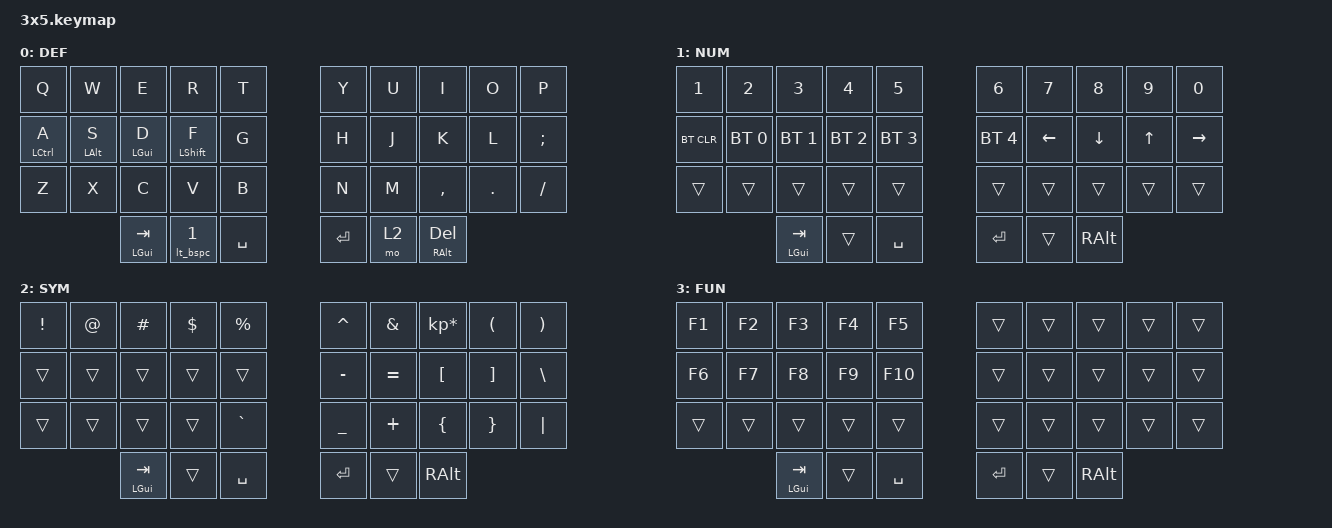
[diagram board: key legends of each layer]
/*
 * Copyright (c) 2020 The ZMK Contributors
 *
 * SPDX-License-Identifier: MIT
 */

#include <behaviors.dtsi>
#include <dt-bindings/zmk/keys.h>
#include <dt-bindings/zmk/bt.h>

// Layer aliases
#define DEF 0
#define NUM 1
#define SUM 2
#define NAV 3

#include "combos.dtsi"

// Behavior configuration
&mt {
    flavor = "hold-preferred";
    tapping-term-ms = <150>;
};

&lt {
    flavor = "balanced";
    tapping-term-ms = <150>;
};

&caps_word {
    continue-list = <UNDERSCORE MINUS BSPC DEL N1 N2 N3 N4 N5 N6 N7 N8 N9 N0>;
};

/ {
    behaviors {
        am: alpha_mods {
            compatible = "zmk,behavior-hold-tap";
            label = "ALPHA_MT";
            #binding-cells = <2>;
            tapping-term-ms = <250>;
            quick-tap-ms = <150>;
            flavor = "tap-preferred";
            bindings = <&kp>, <&kp>;
        };
        as: alpha_shift {
            compatible = "zmk,behavior-hold-tap";
            label = "ALPHA_SFT";
            #binding-cells = <2>;
            tapping-term-ms = <200>;
            quick-tap-ms = <150>;
            flavor = "tap-preferred";
            bindings = <&kp>, <&kp>;
        };

        // Easy alt-tab with alt+backspace thumb using mod-morphs
        bstab: backspace_tab {
            compatible = "zmk,behavior-mod-morph";
            label = "BSPC_TAB";
            #binding-cells = <0>;
            bindings = <&kp BSPC>, <&kp TAB>;
            mods = <MOD_LALT>;
        };
        lt_bspc: layer_tap_backspace_tab {
            compatible = "zmk,behavior-hold-tap";
            label = "LT_BT";
            #binding-cells = <2>;
            tapping-term-ms = <150>;
            flavor = "balanced";
            bindings = <&mo>, <&bstab>;
        };
    };

    cond_layers {
        compatible = "zmk,conditional-layers";
        // Define FUN layer as tri-state
        func_tristate {
            if-layers = <NAV SYM>;
            then-layer = <FUN>;
        };
    };

    macros {
        ZMK_MACRO(inv_qm,
            wait-ms = <10>;
            tap-ms = <10>;
            bindings
                = <&macro_press &kp LALT>
                , <&macro_tap &kp KP_N1 &kp KP_N6 &kp KP_N8>
                , <&macro_release &kp LALT>;
        )
    };

    keymap {
        compatible = "zmk,keymap";

        default_layer {
            label = "DEF";
            bindings = <
    /* ╭─────────────┬─────────────┬─────────────┬─────────────┬─────────────╮╭─────────────┬─────────────┬─────────────┬─────────────┬─────────────╮*/
         &kp Q         &kp W         &kp E         &kp R         &kp T          &kp Y         &kp U         &kp I         &kp O         &kp P
    /*
    ├─────────────┼─────────────┼─────────────┼─────────────┼─────────────┤├─────────────┼─────────────┼─────────────┼─────────────┼─────────────┤*/
      &am LCTRL A   &am LALT S     &am LGUI D   &as LSHFT F      &kp G          &kp H         &kp J         &kp K         &kp L        &kp SEMI
    /*
    ├─────────────┼─────────────┼─────────────┼─────────────┼─────────────┤├─────────────┼─────────────┼─────────────┼─────────────┼─────────────┤
    */
         &kp Z         &kp X         &kp C         &kp V         &kp B          &kp N         &kp M       &kp COMMA      &kp DOT      &kp FSLH
    /*
    ├─────────────┼─────────────┼─────────────┼─────────────┼─────────────┤├─────────────┼─────────────┼─────────────┼─────────────┼─────────────┤*/
                                  &mt LGUI TAB   &lt_bspc 1    &kp SPACE       &kp RET       &mo 2       &mt RALT DEL
    /*
                                ╰─────────────┴─────────────┴─────────────╯╰─────────────┴─────────────┴─────────────╯
    */
            >;
        };

        numbers {
            label = "NUM";
            bindings = <
    /* ╭─────────────┬─────────────┬─────────────┬─────────────┬─────────────╮╭─────────────┬─────────────┬─────────────┬─────────────┬─────────────╮*/
         &kp N1         &kp N2         &kp N3         &kp N4     &kp N5         &kp N6       &kp N7        &kp N8        &kp N9        &kp N0
    /*
    ├─────────────┼─────────────┼─────────────┼─────────────┼─────────────┤├─────────────┼─────────────┼─────────────┼─────────────┼─────────────┤*/
      &bt BT_CLR    &bt BT_SEL 0 &bt BT_SEL 1  &bt BT_SEL 2  &bt BT_SEL 3   &bt BT_SEL 4    &kp LEFT       &kp DOWN      &kp UP       &kp RIGHT
    /*
    ├─────────────┼─────────────┼─────────────┼─────────────┼─────────────┤├─────────────┼─────────────┼─────────────┼─────────────┼─────────────┤
    */
         &trans       &trans         &trans        &trans        &trans        &trans        &trans        &trans        &trans        &trans
    /*
    ├─────────────┼─────────────┼─────────────┼─────────────┼─────────────┤├─────────────┼─────────────┼─────────────┼─────────────┼─────────────┤*/
                                  &mt LGUI TAB    &trans       &kp SPACE        &kp RET      &trans        &kp RALT
    /*
                                ╰─────────────┴─────────────┴─────────────╯╰─────────────┴─────────────┴─────────────╯
    */
            >;
        };

        symbols {
            label = "SYM";
            bindings = <
    /* ╭─────────────┬─────────────┬─────────────┬─────────────┬─────────────╮╭─────────────┬─────────────┬─────────────┬─────────────┬─────────────╮*/
        &kp EXCL      &kp AT       &kp HASH       &kp DLLR     &kp PRCNT      &kp CARET     &kp AMPS   &kp KP_MULTIPLY   &kp LPAR     &kp RPAR
    /*
    ├─────────────┼─────────────┼─────────────┼─────────────┼─────────────┤├─────────────┼─────────────┼─────────────┼─────────────┼─────────────┤*/
        &trans        &trans        &trans        &trans         &trans       &kp MINUS     &kp EQUAL     &kp LBKT      &kp RBKT      &kp BSLH
    /*
    ├─────────────┼─────────────┼─────────────┼─────────────┼─────────────┤├─────────────┼─────────────┼─────────────┼─────────────┼─────────────┤
    */
         &trans       &trans         &trans        &trans      &kp GRAVE      &kp UNDER     &kp PLUS      &kp LBRC      &kp RBRC      &kp PIPE
    /*
    ├─────────────┼─────────────┼─────────────┼─────────────┼─────────────┤├─────────────┼─────────────┼─────────────┼─────────────┼─────────────┤*/
                                  &mt LGUI TAB    &trans       &kp SPACE        &kp RET      &trans        &kp RALT
    /*
                                ╰─────────────┴─────────────┴─────────────╯╰─────────────┴─────────────┴─────────────╯
    */
            >;
        };

        function {
            label = "FUN";
            bindings = <
    /* ╭─────────────┬─────────────┬─────────────┬─────────────┬─────────────╮╭─────────────┬─────────────┬─────────────┬─────────────┬─────────────╮*/
        &kp F1        &kp F2        &kp F3        &kp F4        &kp F5         &trans        &trans        &trans        &trans        &trans
    /*
    ├─────────────┼─────────────┼─────────────┼─────────────┼─────────────┤├─────────────┼─────────────┼─────────────┼─────────────┼─────────────┤*/
        &kp F6        &kp F7        &kp F8        &kp F9        &kp F10        &trans        &trans        &trans        &trans        &trans
    /*
    ├─────────────┼─────────────┼─────────────┼─────────────┼─────────────┤├─────────────┼─────────────┼─────────────┼─────────────┼─────────────┤
    */
         &trans       &trans         &trans        &trans      &trans          &trans        &trans        &trans        &trans        &trans
    /*
    ├─────────────┼─────────────┼─────────────┼─────────────┼─────────────┤├─────────────┼─────────────┼─────────────┼─────────────┼─────────────┤*/
                                  &mt LGUI TAB    &trans       &kp SPACE        &kp RET      &trans        &kp RALT
    /*
                                ╰─────────────┴─────────────┴─────────────╯╰─────────────┴─────────────┴─────────────╯
    */
            >;
        };
    };

};
